AUTOSAR XML (schema 00052)
package /Components
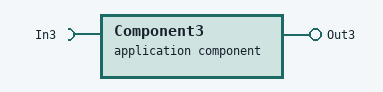
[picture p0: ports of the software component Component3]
  application sw component type Component3
    require port In3
    provide port Out3
